# STM32G07x register map
File version: 1.3
CPU: CM0+ r0p0, little endian, no MPU, no FPU, 3 interrupt priority bits
Registers are 32-bit, read-write, reset 0x0 unless marked. A register's access mark holds for its fields unless they carry their own. Offsets are from the block's base; [hi:lo] are bit positions; {n}, {i} and the like mark numbered series; 'fields as' and 'values as' point back to an identical list.

## EXTI — External interrupt/event controller
Base 0x40021800
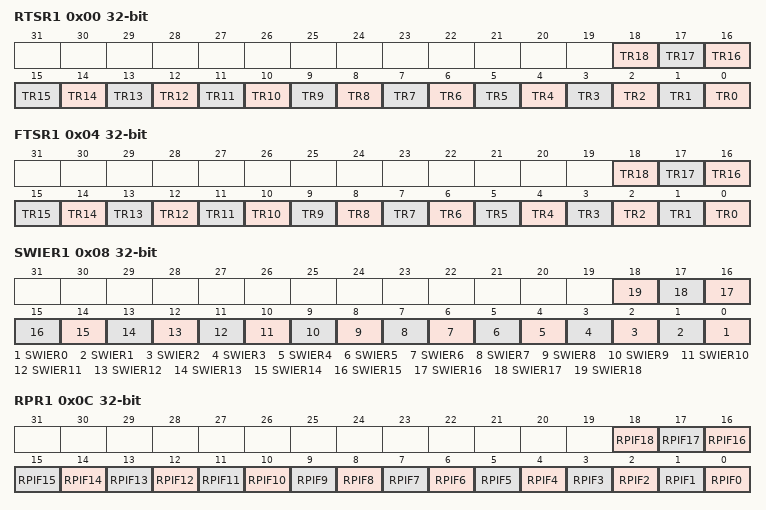
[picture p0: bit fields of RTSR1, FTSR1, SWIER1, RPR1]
0x00 RTSR1 — EXTI rising trigger selection register
  [n] TR{n} (n=0..18) — Rising trigger event configuration bit of Configurable Event input
0x04 FTSR1 — EXTI falling trigger selection register
  fields as RTSR1
0x08 SWIER1 — EXTI software interrupt event register
  [n] SWIER{n} (n=0..18) — Rising trigger event configuration bit of Configurable Event input
0x0C RPR1 — EXTI rising edge pending register
  [n] RPIF{n} (n=6..18) — configurable event inputs x rising edge Pending bit.
  [5] RPIF5 — configurable event inputs x rising edge Pending bit
  [n] RPIF{n} (n=0..4) — configurable event inputs x rising edge Pending bit.
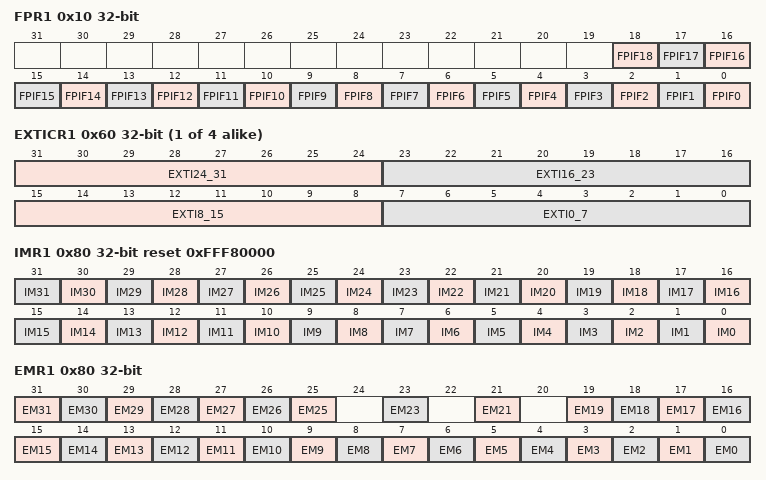
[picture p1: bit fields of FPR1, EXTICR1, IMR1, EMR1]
0x10 FPR1 — EXTI falling edge pending register
  [n] FPIF{n} (n=0..18) — configurable event inputs x falling edge pending bit.
{0x5C+4i} EXTICR{i} (i=1..4) — EXTI external interrupt selection register
  [31:24] EXTI24_31 — GPIO port selection
  [23:16] EXTI16_23 — GPIO port selection
  [15:8] EXTI8_15 — GPIO port selection
  [7:0] EXTI0_7 — GPIO port selection
0x80 IMR1 reset 0xFFF80000 — EXTI CPU wakeup with interrupt mask register
  [n] IM{n} (n=0..31) — CPU wakeup with interrupt mask on event input
0x80 EMR1 (alternate view of IMR1) — EXTI CPU wakeup with event mask register
  [n] EM{n} (n=25..31) — CPU wakeup with event mask on event input
  [23] EM23 — CPU wakeup with event mask on event input
  [21] EM21 — CPU wakeup with event mask on event input
  [n] EM{n} (n=0..19) — CPU wakeup with event mask on event input
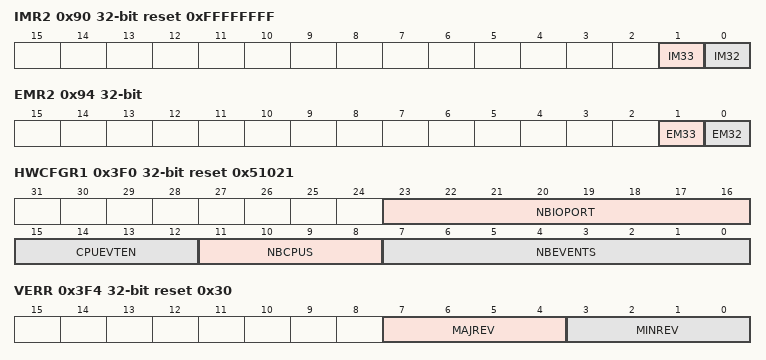
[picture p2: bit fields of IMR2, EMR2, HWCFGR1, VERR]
0x90 IMR2 reset 0xFFFFFFFF — EXTI CPU wakeup with interrupt mask register
  [1] IM33 — CPU wakeup with interrupt mask on event input
  [0] IM32 — CPU wakeup with interrupt mask on event input
0x94 EMR2 — EXTI CPU wakeup with event mask register
  [1] EM33 — CPU wakeup with event mask on event input
  [0] EM32 — CPU wakeup with event mask on event input
0x3D8 HWCFGR7 — Hardware configuration registers
  [31:0] CPUEVENT — HW configuration CPU event generation
0x3DC HWCFGR6 reset 0x3 — Hardware configuration registers
  [31:0] CPUEVENT — HW configuration CPU event generation
0x3E0 HWCFGR5 reset 0xFEAFFFFF — Hardware configuration registers
  [31:0] CPUEVENT — HW configuration CPU event generation
0x3E4 HWCFGR4 — Hardware configuration registers
  [31:0] EVENT_TRG — HW configuration event trigger type
0x3E8 HWCFGR3 — Hardware configuration registers
  [31:0] EVENT_TRG — HW configuration event trigger type
0x3EC HWCFGR2 reset 0x7FFFF — Hardware configuration registers
  [31:0] EVENT_TRG — HW configuration event trigger type
0x3F0 HWCFGR1 ro reset 0x51021 — Hardware configuration registers
  [23:16] NBIOPORT — HW configuration of number of IO ports
  [15:12] CPUEVTEN — HW configuration of CPU event output enable
  [11:8] NBCPUS — configuration number of CPUs
  [7:0] NBEVENTS — configuration number of event
0x3F4 VERR ro reset 0x30 — AES version register
  [7:4] MAJREV — Major revision
  [3:0] MINREV — Minor revision
0x3F8 IPIDR ro reset 0xE0001 — AES identification register
  [31:0] ID — Identification code
0x3FC SIDR ro reset 0xA3C5DD01 — AES size ID register
  [31:0] ID — Size Identification code

## TIM16 — General purpose timers
Base 0x40014400
Same registers: TIM15 0x40014000, TIM17 0x40014800
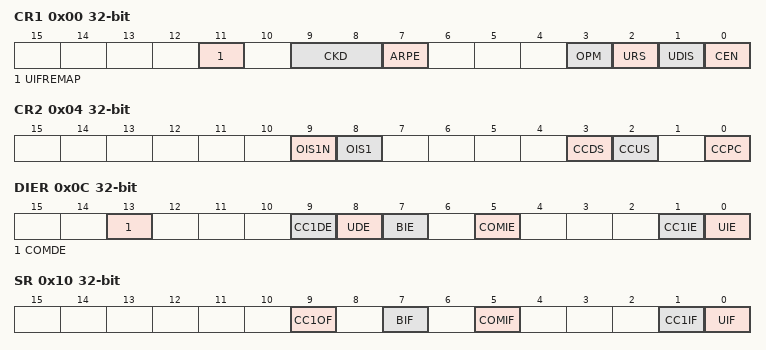
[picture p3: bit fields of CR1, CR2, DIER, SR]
0x00 CR1 — control register 1
  [11] UIFREMAP — UIF status bit remapping
  [9:8] CKD — Clock division
  [7] ARPE — Auto-reload preload enable
  [3] OPM — One-pulse mode
  [2] URS — Update request source
  [1] UDIS — Update disable
  [0] CEN — Counter enable
0x04 CR2 — control register 2
  [9] OIS1N — Output Idle state 1
  [8] OIS1 — Output Idle state 1
  [3] CCDS — Capture/compare DMA selection
  [2] CCUS — Capture/compare control update selection
  [0] CCPC — Capture/compare preloaded control
0x0C DIER — DMA/Interrupt enable register
  [13] COMDE — COM DMA request enable
  [9] CC1DE — Capture/Compare 1 DMA request enable
  [8] UDE — Update DMA request enable
  [7] BIE — Break interrupt enable
  [5] COMIE — COM interrupt enable
  [1] CC1IE — Capture/Compare 1 interrupt enable
  [0] UIE — Update interrupt enable
0x10 SR — status register
  [9] CC1OF — Capture/Compare 1 overcapture flag
  [7] BIF — Break interrupt flag
  [5] COMIF — COM interrupt flag
  [1] CC1IF — Capture/compare 1 interrupt flag
  [0] UIF — Update interrupt flag
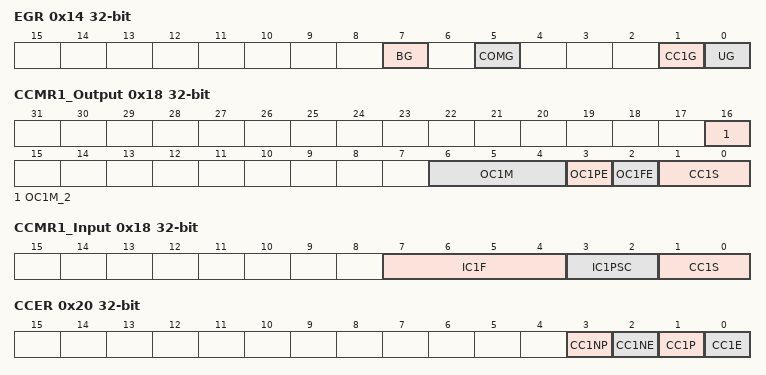
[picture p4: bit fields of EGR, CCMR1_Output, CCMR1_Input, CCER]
0x14 EGR wo — event generation register
  [7] BG — Break generation
  [5] COMG — Capture/Compare control update generation
  [1] CC1G — Capture/compare 1 generation
  [0] UG — Update generation
0x18 CCMR1_Output — capture/compare mode register (output mode)
  [16] OC1M_2 — Output Compare 1 mode
  [6:4] OC1M — Output Compare 1 mode
  [3] OC1PE — Output Compare 1 preload enable
  [2] OC1FE — Output Compare 1 fast enable
  [1:0] CC1S — Capture/Compare 1 selection
0x18 CCMR1_Input (alternate view of CCMR1_Output) — capture/compare mode register 1 (input mode)
  [7:4] IC1F — Input capture 1 filter
  [3:2] IC1PSC — Input capture 1 prescaler
  [1:0] CC1S — Capture/Compare 1 selection
0x20 CCER — capture/compare enable register
  [3] CC1NP — Capture/Compare 1 output Polarity
  [2] CC1NE — Capture/Compare 1 complementary output enable
  [1] CC1P — Capture/Compare 1 output Polarity
  [0] CC1E — Capture/Compare 1 output enable
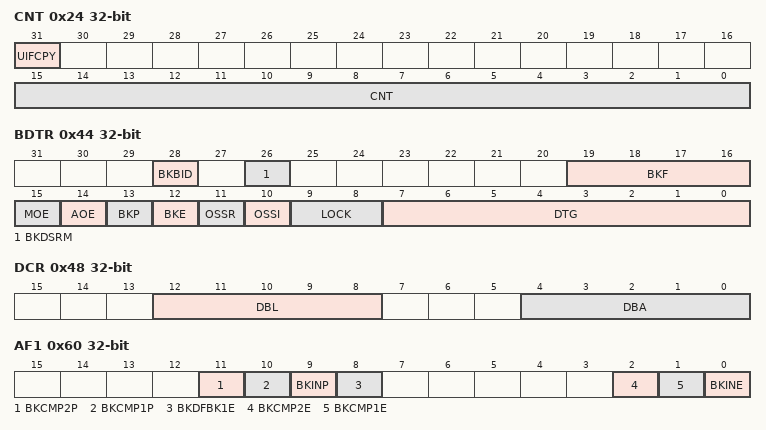
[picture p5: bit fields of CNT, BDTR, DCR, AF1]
0x24 CNT access per field — counter
  [31] UIFCPY ro — UIF Copy
  [15:0] CNT rw — counter value
0x28 PSC — prescaler
  [15:0] PSC — Prescaler value
0x2C ARR — auto-reload register
  [15:0] ARR — Auto-reload value
0x30 RCR — repetition counter register
  [7:0] REP — Repetition counter value
0x34 CCR1 — capture/compare register 1
  [15:0] CCR1 — Capture/Compare 1 value
0x44 BDTR — break and dead-time register
  [28] BKBID — Break Bidirectional
  [26] BKDSRM — Break Disarm
  [19:16] BKF — Break filter
  [15] MOE — Main output enable
  [14] AOE — Automatic output enable
  [13] BKP — Break polarity
  [12] BKE — Break enable
  [11] OSSR — Off-state selection for Run mode
  [10] OSSI — Off-state selection for Idle mode
  [9:8] LOCK — Lock configuration
  [7:0] DTG — Dead-time generator setup
0x48 DCR — DMA control register
  [12:8] DBL — DMA burst length
  [4:0] DBA — DMA base address
0x4C DMAR — DMA address for full transfer
  [15:0] DMAB — DMA register for burst accesses
0x60 AF1 — TIM17 option register 1
  [11] BKCMP2P — BRK COMP2 input polarit
  [10] BKCMP1P — BRK COMP1 input polarity
  [9] BKINP — BRK BKIN input polarity
  [8] BKDFBK1E — BRK DFSDM_BREAK1 enable
  [2] BKCMP2E — BRK COMP2 enable
  [1] BKCMP1E — BRK COMP1 enable
  [0] BKINE — BRK BKIN input enable
0x68 TISEL — input selection register
  [3:0] TI1SEL — selects input
